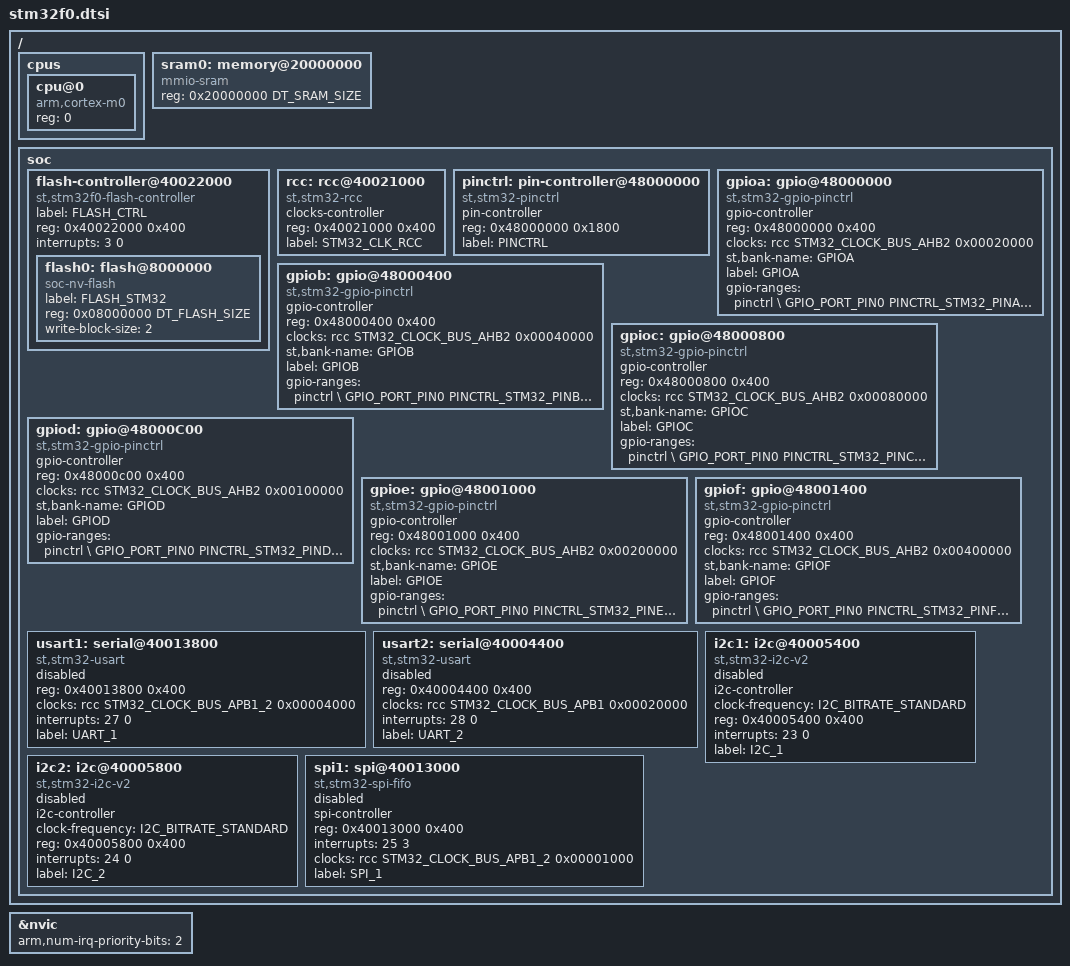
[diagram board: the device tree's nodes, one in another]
/*
 * Copyright (c) 2017 RnDity Sp. z o.o.
 *
 * SPDX-License-Identifier: Apache-2.0
 */

#include <st/mem.h>
#include <dt-bindings/clock/stm32_clock.h>
#include <dt-bindings/i2c/i2c.h>
#include <dt-bindings/gpio/gpio.h>
#include <dt-bindings/pinctrl/pinctrl_stm32.h>

#include <arm/armv6-m.dtsi>
#include <st/stm32f0-pinctrl.dtsi>

/ {
	cpus {
		#address-cells = <1>;
		#size-cells = <0>;

		cpu@0 {
			device_type = "cpu";
			compatible = "arm,cortex-m0";
			reg = <0>;
		};
	};

	sram0: memory@20000000 {
		device_type = "memory";
		compatible = "mmio-sram";
		reg = <0x20000000 DT_SRAM_SIZE>;
	};

	soc {
		flash-controller@40022000 {
			compatible = "st,stm32f0-flash-controller";
			label = "FLASH_CTRL";
			reg = <0x40022000 0x400>;
			interrupts = <3 0>;

			#address-cells = <1>;
			#size-cells = <1>;

			flash0: flash@8000000 {
				compatible = "soc-nv-flash";
				label = "FLASH_STM32";
				reg = <0x08000000 DT_FLASH_SIZE>;

				write-block-size = <2>;
			};
		};

		rcc: rcc@40021000 {
			compatible = "st,stm32-rcc";
			clocks-controller;
			#clocks-cells = <2>;
			reg = <0x40021000 0x400>;
			label = "STM32_CLK_RCC";
		};

		pinctrl: pin-controller@48000000 {
			compatible = "st,stm32-pinctrl";
			pin-controller;
			#address-cells = <1>;
			#size-cells = <1>;
			reg = <0x48000000 0x1800>;
			label = "PINCTRL";
		};

		gpioa: gpio@48000000 {
			compatible = "st,stm32-gpio-pinctrl";
			gpio-controller;
			#gpio-cells = <2>;
			reg = <0x48000000 0x400>;
			clocks = <&rcc STM32_CLOCK_BUS_AHB2 0x00020000>;
			st,bank-name = "GPIOA";
			label = "GPIOA";
			gpio-ranges = <&pinctrl \
				GPIO_PORT_PIN0 PINCTRL_STM32_PINA0 16>;
		};

		gpiob: gpio@48000400 {
			compatible = "st,stm32-gpio-pinctrl";
			gpio-controller;
			#gpio-cells = <2>;
			reg = <0x48000400 0x400>;
			clocks = <&rcc STM32_CLOCK_BUS_AHB2 0x00040000>;
			st,bank-name = "GPIOB";
			label = "GPIOB";
			gpio-ranges = <&pinctrl \
				GPIO_PORT_PIN0 PINCTRL_STM32_PINB0 16>;
		};

		gpioc: gpio@48000800 {
			compatible = "st,stm32-gpio-pinctrl";
			gpio-controller;
			#gpio-cells = <2>;
			reg = <0x48000800 0x400>;
			clocks = <&rcc STM32_CLOCK_BUS_AHB2 0x00080000>;
			st,bank-name = "GPIOC";
			label = "GPIOC";
			gpio-ranges = <&pinctrl \
				GPIO_PORT_PIN0 PINCTRL_STM32_PINC0 16>;
		};

		gpiod: gpio@48000C00 {
			compatible = "st,stm32-gpio-pinctrl";
			gpio-controller;
			#gpio-cells = <2>;
			reg = <0x48000c00 0x400>;
			clocks = <&rcc STM32_CLOCK_BUS_AHB2 0x00100000>;
			st,bank-name = "GPIOD";
			label = "GPIOD";
			gpio-ranges = <&pinctrl \
				GPIO_PORT_PIN0 PINCTRL_STM32_PIND0 16>;
		};

		gpioe: gpio@48001000 {
			compatible = "st,stm32-gpio-pinctrl";
			gpio-controller;
			#gpio-cells = <2>;
			reg = <0x48001000 0x400>;
			clocks = <&rcc STM32_CLOCK_BUS_AHB2 0x00200000>;
			st,bank-name = "GPIOE";
			label = "GPIOE";
			gpio-ranges = <&pinctrl \
				GPIO_PORT_PIN0 PINCTRL_STM32_PINE0 16>;
		};

		gpiof: gpio@48001400 {
			compatible = "st,stm32-gpio-pinctrl";
			gpio-controller;
			#gpio-cells = <2>;
			reg = <0x48001400 0x400>;
			clocks = <&rcc STM32_CLOCK_BUS_AHB2 0x00400000>;
			st,bank-name = "GPIOF";
			label = "GPIOF";
			gpio-ranges = <&pinctrl \
				GPIO_PORT_PIN0 PINCTRL_STM32_PINF0 16>;
		};

		usart1: serial@40013800 {
			compatible = "st,stm32-usart", "st,stm32-uart";
			reg = <0x40013800 0x400>;
			clocks = <&rcc STM32_CLOCK_BUS_APB1_2 0x00004000>;
			interrupts = <27 0>;
			status = "disabled";
			label = "UART_1";
		};

		usart2: serial@40004400 {
			compatible = "st,stm32-usart", "st,stm32-uart";
			reg = <0x40004400 0x400>;
			clocks = <&rcc STM32_CLOCK_BUS_APB1 0x00020000>;
			interrupts = <28 0>;
			status = "disabled";
			label = "UART_2";
		};

		i2c1: i2c@40005400 {
			i2c-controller;
			compatible = "st,stm32-i2c-v2";
			clock-frequency = <I2C_BITRATE_STANDARD>;
			#address-cells = <1>;
			#size-cells = <0>;
			reg = <0x40005400 0x400>;
			interrupts = <23 0>;
			interrupt-names = "combined";
			status = "disabled";
			label= "I2C_1";
		};

		i2c2: i2c@40005800 {
			i2c-controller;
			compatible = "st,stm32-i2c-v2";
			clock-frequency = <I2C_BITRATE_STANDARD>;
			#address-cells = <1>;
			#size-cells = <0>;
			reg = <0x40005800 0x400>;
			interrupts = <24 0>;
			interrupt-names = "combined";
			status = "disabled";
			label= "I2C_2";
		};

		spi1: spi@40013000 {
			spi-controller;
			compatible = "st,stm32-spi-fifo";
			#address-cells = <1>;
			#size-cells = <0>;
			reg = <0x40013000 0x400>;
			interrupts = <25 3>;
			clocks = <&rcc STM32_CLOCK_BUS_APB1_2 0x00001000>;
			status = "disabled";
			label = "SPI_1";
		};

	};
};

&nvic {
	arm,num-irq-priority-bits = <2>;
};
